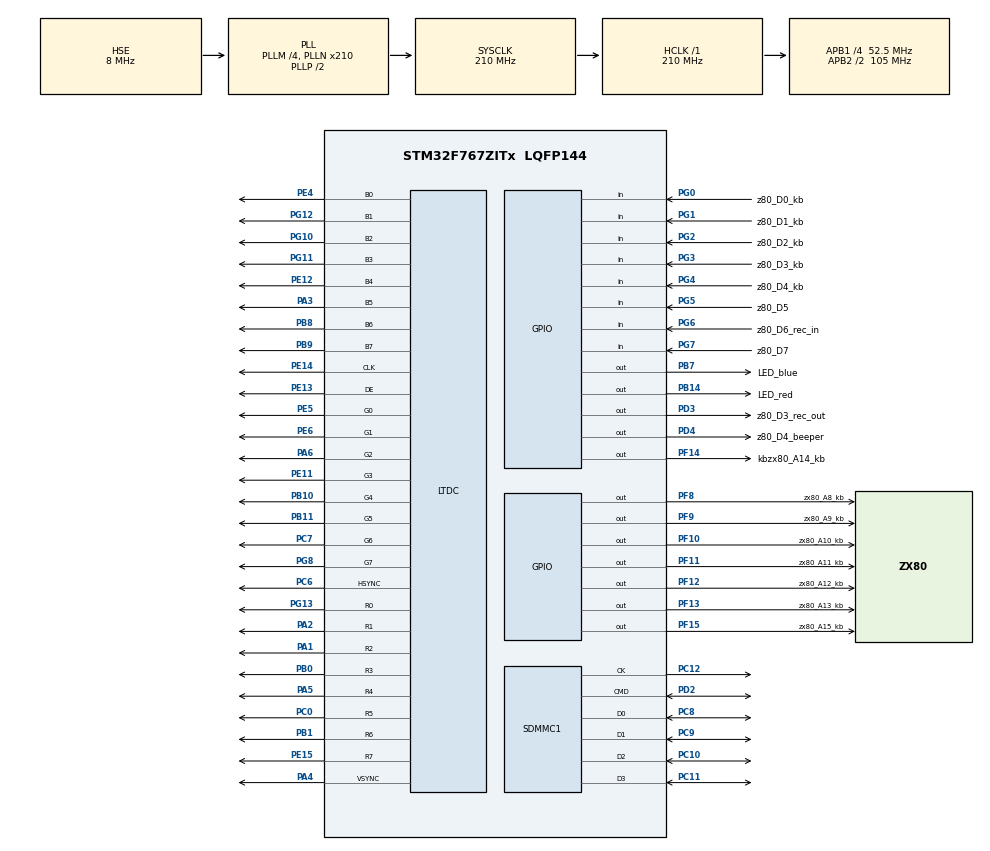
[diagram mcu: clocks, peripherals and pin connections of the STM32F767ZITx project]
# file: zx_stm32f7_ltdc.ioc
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CORTEX_M7.CPU_DCache=Enabled
CORTEX_M7.CPU_ICache=Enabled
CORTEX_M7.FlashInterface=TCM_Enabled
CORTEX_M7.PREFETCH_ENABLE=1
Dma.MEMTOMEM.0.Direction=DMA_MEMORY_TO_MEMORY
Dma.MEMTOMEM.0.FIFOMode=DMA_FIFOMODE_ENABLE
Dma.MEMTOMEM.0.FIFOThreshold=DMA_FIFO_THRESHOLD_FULL
Dma.MEMTOMEM.0.Instance=DMA2_Stream1
Dma.MEMTOMEM.0.MemBurst=DMA_MBURST_SINGLE
Dma.MEMTOMEM.0.MemDataAlignment=DMA_MDATAALIGN_HALFWORD
Dma.MEMTOMEM.0.MemInc=DMA_MINC_ENABLE
Dma.MEMTOMEM.0.Mode=DMA_NORMAL
Dma.MEMTOMEM.0.PeriphBurst=DMA_PBURST_SINGLE
Dma.MEMTOMEM.0.PeriphDataAlignment=DMA_PDATAALIGN_HALFWORD
Dma.MEMTOMEM.0.PeriphInc=DMA_PINC_ENABLE
Dma.MEMTOMEM.0.Priority=DMA_PRIORITY_HIGH
Dma.Request0=MEMTOMEM
FATFS.USE_DMA_CODE_SD=0
FATFS._MAX_SS=4096
LTDC.ActiveH=272
LTDC.ActiveW=384
LTDC.Alpha0_L0=0
LTDC.Alpha_L0=255
LTDC.BlendingFactor1_L0=LTDC_BLENDING_FACTOR1_PAxCA
LTDC.BlendingFactor2_L0=LTDC_BLENDING_FACTOR2_PAxCA
LTDC.DEPolarity=LTDC_DEPOLARITY_AL
LTDC.HBP=42
LTDC.HFP=8
LTDC.HSPolarity=LTDC_HSPOLARITY_AL
LTDC.HSync=14
LTDC.ImageHeight_L0=192
LTDC.ImageWidth_L0=256
LTDC.Layers=0
LTDC.PixelFormat_L0=LTDC_PIXEL_FORMAT_RGB565
LTDC.VBP=12
LTDC.VFP=4
LTDC.VSPolarity=LTDC_VSPOLARITY_AL
LTDC.VSync=32
LTDC.WindowX0_L0=64
LTDC.WindowX1_L0=320
LTDC.WindowY0_L0=40
LTDC.WindowY1_L0=232
Mcu.Family=STM32F7
Mcu.Name=STM32F767ZITx
Mcu.Package=LQFP144
NVIC.PriorityGroup=NVIC_PRIORITYGROUP_4
NVIC.TIM8_TRG_COM_TIM14_IRQn=true\:0\:0\:false\:false\:true\:true
PA1.GPIO_Speed=GPIO_SPEED_FREQ_VERY_HIGH
PA1.Mode=RGB888
PA1.Signal=LTDC_R2
PA2.GPIO_Speed=GPIO_SPEED_FREQ_VERY_HIGH
PA2.Mode=RGB888
PA2.Signal=LTDC_R1
PA3.GPIO_Speed=GPIO_SPEED_FREQ_VERY_HIGH
PA3.Mode=RGB888
PA3.Signal=LTDC_B5
PA4.GPIO_Speed=GPIO_SPEED_FREQ_VERY_HIGH
PA4.Mode=RGB888
PA4.Signal=LTDC_VSYNC
PA5.GPIO_Speed=GPIO_SPEED_FREQ_VERY_HIGH
PA5.Mode=RGB888
PA5.Signal=LTDC_R4
PA6.GPIO_Speed=GPIO_SPEED_FREQ_VERY_HIGH
PA6.Mode=RGB888
PA6.Signal=LTDC_G2
PB0.GPIO_Speed=GPIO_SPEED_FREQ_VERY_HIGH
PB0.Mode=RGB888
PB0.Signal=LTDC_R3
PB1.GPIO_Speed=GPIO_SPEED_FREQ_VERY_HIGH
PB1.Mode=RGB888
PB1.Signal=LTDC_R6
PB10.GPIO_Speed=GPIO_SPEED_FREQ_VERY_HIGH
PB10.Mode=RGB888
PB10.Signal=LTDC_G4
PB11.GPIO_Speed=GPIO_SPEED_FREQ_VERY_HIGH
PB11.Mode=RGB888
PB11.Signal=LTDC_G5
PB14.GPIO_Label=LED_red
PB14.GPIO_Speed=GPIO_SPEED_FREQ_HIGH
PB14.Signal=GPIO_Output
PB7.GPIO_Label=LED_blue
PB7.GPIO_Speed=GPIO_SPEED_FREQ_HIGH
PB7.Signal=GPIO_Output
PB8.GPIO_Speed=GPIO_SPEED_FREQ_VERY_HIGH
PB8.Mode=RGB888
PB8.Signal=LTDC_B6
PB9.GPIO_Speed=GPIO_SPEED_FREQ_VERY_HIGH
PB9.Mode=RGB888
PB9.Signal=LTDC_B7
PC0.GPIO_Speed=GPIO_SPEED_FREQ_VERY_HIGH
PC0.Mode=RGB888
PC0.Signal=LTDC_R5
PC10.GPIO_PuPd=GPIO_PULLUP
PC10.Mode=SD_4_bits_Wide_bus
PC10.Signal=SDMMC1_D2
PC11.GPIO_PuPd=GPIO_PULLUP
PC11.Mode=SD_4_bits_Wide_bus
PC11.Signal=SDMMC1_D3
PC12.GPIO_PuPd=GPIO_PULLUP
PC12.Mode=SD_4_bits_Wide_bus
PC12.Signal=SDMMC1_CK
PC6.GPIO_Speed=GPIO_SPEED_FREQ_VERY_HIGH
PC6.Mode=RGB888
PC6.Signal=LTDC_HSYNC
PC7.GPIO_Speed=GPIO_SPEED_FREQ_VERY_HIGH
PC7.Mode=RGB888
PC7.Signal=LTDC_G6
PC8.GPIO_PuPd=GPIO_PULLUP
PC8.Mode=SD_4_bits_Wide_bus
PC8.Signal=SDMMC1_D0
PC9.GPIO_PuPd=GPIO_PULLUP
PC9.Mode=SD_4_bits_Wide_bus
PC9.Signal=SDMMC1_D1
PD2.GPIO_PuPd=GPIO_PULLUP
PD2.Mode=SD_4_bits_Wide_bus
PD2.Signal=SDMMC1_CMD
PD3.GPIO_Label=z80_D3_rec_out
PD3.GPIO_Speed=GPIO_SPEED_FREQ_HIGH
PD3.Signal=GPIO_Output
PD4.GPIO_Label=z80_D4_beeper
PD4.GPIO_Speed=GPIO_SPEED_FREQ_HIGH
PD4.Signal=GPIO_Output
PE11.GPIO_Speed=GPIO_SPEED_FREQ_VERY_HIGH
PE11.Mode=RGB888
PE11.Signal=LTDC_G3
PE12.GPIO_Speed=GPIO_SPEED_FREQ_VERY_HIGH
PE12.Mode=RGB888
PE12.Signal=LTDC_B4
PE13.GPIO_Speed=GPIO_SPEED_FREQ_VERY_HIGH
PE13.Mode=RGB888
PE13.Signal=LTDC_DE
PE14.GPIO_Speed=GPIO_SPEED_FREQ_VERY_HIGH
PE14.Mode=RGB888
PE14.Signal=LTDC_CLK
PE15.GPIO_Speed=GPIO_SPEED_FREQ_VERY_HIGH
PE15.Mode=RGB888
PE15.Signal=LTDC_R7
PE4.GPIO_Speed=GPIO_SPEED_FREQ_VERY_HIGH
PE4.Mode=RGB888
PE4.Signal=LTDC_B0
PE5.GPIO_Speed=GPIO_SPEED_FREQ_VERY_HIGH
PE5.Mode=RGB888
PE5.Signal=LTDC_G0
PE6.GPIO_Speed=GPIO_SPEED_FREQ_VERY_HIGH
PE6.Mode=RGB888
PE6.Signal=LTDC_G1
PF10.GPIO_Label=zx80_A10_kb
PF10.GPIO_ModeDefaultOutputPP=GPIO_MODE_OUTPUT_OD
PF10.GPIO_PuPd=GPIO_PULLUP
PF10.GPIO_Speed=GPIO_SPEED_FREQ_VERY_HIGH
PF10.Signal=GPIO_Output
PF11.GPIO_Label=zx80_A11_kb
PF11.GPIO_ModeDefaultOutputPP=GPIO_MODE_OUTPUT_OD
PF11.GPIO_PuPd=GPIO_PULLUP
PF11.GPIO_Speed=GPIO_SPEED_FREQ_VERY_HIGH
PF11.Signal=GPIO_Output
PF12.GPIO_Label=zx80_A12_kb
PF12.GPIO_ModeDefaultOutputPP=GPIO_MODE_OUTPUT_OD
PF12.GPIO_PuPd=GPIO_PULLUP
PF12.GPIO_Speed=GPIO_SPEED_FREQ_VERY_HIGH
PF12.Signal=GPIO_Output
PF13.GPIO_Label=zx80_A13_kb
PF13.GPIO_ModeDefaultOutputPP=GPIO_MODE_OUTPUT_OD
PF13.GPIO_PuPd=GPIO_PULLUP
PF13.GPIO_Speed=GPIO_SPEED_FREQ_VERY_HIGH
PF13.Signal=GPIO_Output
PF14.GPIO_Label=kbzx80_A14_kb
PF14.GPIO_ModeDefaultOutputPP=GPIO_MODE_OUTPUT_OD
PF14.GPIO_PuPd=GPIO_PULLUP
PF14.GPIO_Speed=GPIO_SPEED_FREQ_VERY_HIGH
PF14.Signal=GPIO_Output
PF15.GPIO_Label=zx80_A15_kb
PF15.GPIO_ModeDefaultOutputPP=GPIO_MODE_OUTPUT_OD
PF15.GPIO_PuPd=GPIO_PULLUP
PF15.GPIO_Speed=GPIO_SPEED_FREQ_VERY_HIGH
PF15.Signal=GPIO_Output
PF8.GPIO_Label=zx80_A8_kb
PF8.GPIO_ModeDefaultOutputPP=GPIO_MODE_OUTPUT_OD
PF8.GPIO_PuPd=GPIO_PULLUP
PF8.GPIO_Speed=GPIO_SPEED_FREQ_VERY_HIGH
PF8.Signal=GPIO_Output
PF9.GPIO_Label=zx80_A9_kb
PF9.GPIO_ModeDefaultOutputPP=GPIO_MODE_OUTPUT_OD
PF9.GPIO_PuPd=GPIO_PULLUP
PF9.GPIO_Speed=GPIO_SPEED_FREQ_VERY_HIGH
PF9.Signal=GPIO_Output
PG0.GPIO_Label=z80_D0_kb
PG0.GPIO_Mode=GPIO_MODE_INPUT
PG0.GPIO_PuPd=GPIO_PULLUP
PG0.Signal=GPIO_Input
PG1.GPIO_Label=z80_D1_kb
PG1.GPIO_Mode=GPIO_MODE_INPUT
PG1.GPIO_PuPd=GPIO_PULLUP
PG1.Signal=GPIO_Input
PG10.GPIO_Speed=GPIO_SPEED_FREQ_VERY_HIGH
PG10.Mode=RGB888
PG10.Signal=LTDC_B2
PG11.GPIO_Speed=GPIO_SPEED_FREQ_VERY_HIGH
PG11.Mode=RGB888
PG11.Signal=LTDC_B3
PG12.GPIO_Speed=GPIO_SPEED_FREQ_VERY_HIGH
PG12.Mode=RGB888
PG12.Signal=LTDC_B1
PG13.GPIO_Speed=GPIO_SPEED_FREQ_VERY_HIGH
PG13.Mode=RGB888
PG13.Signal=LTDC_R0
PG2.GPIO_Label=z80_D2_kb
PG2.GPIO_Mode=GPIO_MODE_INPUT
PG2.GPIO_PuPd=GPIO_PULLUP
PG2.Signal=GPIO_Input
PG3.GPIO_Label=z80_D3_kb
PG3.GPIO_Mode=GPIO_MODE_INPUT
PG3.GPIO_PuPd=GPIO_PULLUP
PG3.Signal=GPIO_Input
PG4.GPIO_Label=z80_D4_kb
PG4.GPIO_Mode=GPIO_MODE_INPUT
PG4.GPIO_PuPd=GPIO_PULLUP
PG4.Signal=GPIO_Input
PG5.GPIO_Label=z80_D5
PG5.GPIO_Mode=GPIO_MODE_INPUT
PG5.GPIO_PuPd=GPIO_PULLUP
PG5.Signal=GPIO_Input
PG6.GPIO_Label=z80_D6_rec_in
PG6.GPIO_Mode=GPIO_MODE_INPUT
PG6.GPIO_PuPd=GPIO_PULLUP
PG6.Signal=GPIO_Input
PG7.GPIO_Label=z80_D7
PG7.GPIO_Mode=GPIO_MODE_INPUT
PG7.GPIO_PuPd=GPIO_PULLUP
PG7.Signal=GPIO_Input
PG8.GPIO_Speed=GPIO_SPEED_FREQ_VERY_HIGH
PG8.Mode=RGB888
PG8.Signal=LTDC_G7
PH0/OSC_IN.Mode=HSE-External-Oscillator
PH0/OSC_IN.Signal=RCC_OSC_IN
PH1/OSC_OUT.Mode=HSE-External-Oscillator
PH1/OSC_OUT.Signal=RCC_OSC_OUT
ProjectManager.HeapSize=0x200
ProjectManager.StackSize=0x400
ProjectManager.TargetToolchain=SW4STM32
RCC.AHBFreq_Value=210000000
RCC.APB1CLKDivider=RCC_HCLK_DIV4
RCC.APB1Freq_Value=52500000
RCC.APB1TimFreq_Value=105000000
RCC.APB2CLKDivider=RCC_HCLK_DIV2
RCC.APB2Freq_Value=105000000
RCC.APB2TimFreq_Value=210000000
RCC.CortexFreq_Value=210000000
RCC.HCLKFreq_Value=210000000
RCC.HSE_VALUE=8000000
RCC.HSI_VALUE=16000000
RCC.LSE_VALUE=32768
RCC.PLLM=4
RCC.PLLN=210
RCC.PLLQ=15
RCC.PLLSAIN=98
RCC.PLLSAIP=RCC_PLLSAIP_DIV6
RCC.PLLSAIR=7
RCC.PLLSAIRDiv=RCC_PLLSAIDIVR_4
RCC.PLLSourceVirtual=RCC_PLLSOURCE_HSE
RCC.SDMMCClockSelection=RCC_SDMMC1CLKSOURCE_CLK48
RCC.SYSCLKFreq_VALUE=210000000
RCC.SYSCLKSource=RCC_SYSCLKSOURCE_PLLCLK
RCC.USBFreq_Value=28000000
RCC.VCOOutputFreq_Value=420000000
TIM13.AutoReloadPreload=TIM_AUTORELOAD_PRELOAD_ENABLE
TIM13.Channel=TIM_CHANNEL_1
TIM13.Period=10239
TIM13.Prescaler=209
TIM14.Channel=TIM_CHANNEL_1
TIM14.Period=65535
TIM14.Prescaler=29
VP_FATFS_VS_SDIO.Mode=SDIO
VP_RNG_VS_RNG.Mode=RNG_Activate
VP_TIM13_VS_ClockSourceINT.Mode=Enable_Timer
VP_TIM13_VS_no_output1.Mode=Output Compare1 No Output
VP_TIM14_VS_ClockSourceINT.Mode=Enable_Timer
VP_TIM14_VS_no_output1.Mode=Output Compare1 No Output
board=zx_stm32f7_ltdc

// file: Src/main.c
/**
  ******************************************************************************
  * @file           : main.c
  * @brief          : Main program body
  ******************************************************************************
  * This notice applies to any and all portions of this file
  * that are not between comment pairs USER CODE BEGIN and
  * USER CODE END. Other portions of this file, whether
  * inserted by the user or by software development tools
  * are owned by their respective copyright owners.
  *
  * Copyright (c) 2018 STMicroelectronics International N.V.
  * All rights reserved.
  *
  * Redistribution and use in source and binary forms, with or without
  * modification, are permitted, provided that the following conditions are met:
  *
  * 1. Redistribution of source code must retain the above copyright notice,
  *    this list of conditions and the following disclaimer.
  * 2. Redistributions in binary form must reproduce the above copyright notice,
  *    this list of conditions and the following disclaimer in the documentation
  *    and/or other materials provided with the distribution.
  * 3. Neither the name of STMicroelectronics nor the names of other
  *    contributors to this software may be used to endorse or promote products
  *    derived from this software without specific written permission.
  * 4. This software, including modifications and/or derivative works of this
  *    software, must execute solely and exclusively on microcontroller or
  *    microprocessor devices manufactured by or for STMicroelectronics.
  * 5. Redistribution and use of this software other than as permitted under
  *    this license is void and will automatically terminate your rights under
  *    this license.
  *
  * THIS SOFTWARE IS PROVIDED BY STMICROELECTRONICS AND CONTRIBUTORS "AS IS"
  * AND ANY EXPRESS, IMPLIED OR STATUTORY WARRANTIES, INCLUDING, BUT NOT
  * LIMITED TO, THE IMPLIED WARRANTIES OF MERCHANTABILITY, FITNESS FOR A
  * PARTICULAR PURPOSE AND NON-INFRINGEMENT OF THIRD PARTY INTELLECTUAL PROPERTY
  * RIGHTS ARE DISCLAIMED TO THE FULLEST EXTENT PERMITTED BY LAW. IN NO EVENT
  * SHALL STMICROELECTRONICS OR CONTRIBUTORS BE LIABLE FOR ANY DIRECT, INDIRECT,
  * INCIDENTAL, SPECIAL, EXEMPLARY, OR CONSEQUENTIAL DAMAGES (INCLUDING, BUT NOT
  * LIMITED TO, PROCUREMENT OF SUBSTITUTE GOODS OR SERVICES; LOSS OF USE, DATA,
  * OR PROFITS; OR BUSINESS INTERRUPTION) HOWEVER CAUSED AND ON ANY THEORY OF
  * LIABILITY, WHETHER IN CONTRACT, STRICT LIABILITY, OR TORT (INCLUDING
  * NEGLIGENCE OR OTHERWISE) ARISING IN ANY WAY OUT OF THE USE OF THIS SOFTWARE,
  * EVEN IF ADVISED OF THE POSSIBILITY OF SUCH DAMAGE.
  *
  ******************************************************************************
  */
#include "main.h"
#include "stm32f7xx_hal.h"
#include "dma.h"
#include "fatfs.h"
#include "ltdc.h"
#include "rng.h"
#include "sdmmc.h"
#include "tim.h"
#include "gpio.h"

/* USER CODE BEGIN Includes */
#include "zx80.h"
/* USER CODE END Includes */

/* USER CODE BEGIN PV */
/* Private variables ---------------------------------------------------------*/

/* USER CODE END PV */

void SystemClock_Config(void);

/* USER CODE BEGIN PFP */
/* Private function prototypes -----------------------------------------------*/

/* USER CODE END PFP */

int main(void)
{

  /* Enable I-Cache-------------------------------------------------------------*/
  SCB_EnableICache();

  /* Enable D-Cache-------------------------------------------------------------*/
  SCB_EnableDCache();

  /* MCU Configuration----------------------------------------------------------*/

  /* Reset of all peripherals, Initializes the Flash interface and the Systick. */
  HAL_Init();

  /* Configure the system clock */
  SystemClock_Config();

  /* Initialize all configured peripherals */
  MX_GPIO_Init();
  MX_DMA_Init();
  MX_LTDC_Init();
  MX_RNG_Init();
  MX_TIM14_Init();
  MX_TIM13_Init();
  MX_SDMMC1_SD_Init();
  MX_FATFS_Init();
  /* USER CODE BEGIN 2 */

  //zx80_Init();
  zx80_load();

  /* USER CODE END 2 */

  /* Infinite loop */
  while (1)
  {

  }

}

void SystemClock_Config(void)
{

  RCC_OscInitTypeDef RCC_OscInitStruct;
  RCC_ClkInitTypeDef RCC_ClkInitStruct;
  RCC_PeriphCLKInitTypeDef PeriphClkInitStruct;

    /**Configure the main internal regulator output voltage
    */
  __HAL_RCC_PWR_CLK_ENABLE();

  __HAL_PWR_VOLTAGESCALING_CONFIG(PWR_REGULATOR_VOLTAGE_SCALE1);

    /**Initializes the CPU, AHB and APB busses clocks
    */
  RCC_OscInitStruct.OscillatorType = RCC_OSCILLATORTYPE_HSE;
  RCC_OscInitStruct.HSEState = RCC_HSE_ON;
  RCC_OscInitStruct.PLL.PLLState = RCC_PLL_ON;
  RCC_OscInitStruct.PLL.PLLSource = RCC_PLLSOURCE_HSE;
  RCC_OscInitStruct.PLL.PLLM = 4;
  RCC_OscInitStruct.PLL.PLLN = 210;
  RCC_OscInitStruct.PLL.PLLP = RCC_PLLP_DIV2;
  RCC_OscInitStruct.PLL.PLLQ = 15;
  if (HAL_RCC_OscConfig(&RCC_OscInitStruct) != HAL_OK)
  {
    _Error_Handler(__FILE__, __LINE__);
  }

    /**Activate the Over-Drive mode
    */
  if (HAL_PWREx_EnableOverDrive() != HAL_OK)
  {
    _Error_Handler(__FILE__, __LINE__);
  }

    /**Initializes the CPU, AHB and APB busses clocks
    */
  RCC_ClkInitStruct.ClockType = RCC_CLOCKTYPE_HCLK|RCC_CLOCKTYPE_SYSCLK
                              |RCC_CLOCKTYPE_PCLK1|RCC_CLOCKTYPE_PCLK2;
  RCC_ClkInitStruct.SYSCLKSource = RCC_SYSCLKSOURCE_PLLCLK;
  RCC_ClkInitStruct.AHBCLKDivider = RCC_SYSCLK_DIV1;
  RCC_ClkInitStruct.APB1CLKDivider = RCC_HCLK_DIV4;
  RCC_ClkInitStruct.APB2CLKDivider = RCC_HCLK_DIV2;

  if (HAL_RCC_ClockConfig(&RCC_ClkInitStruct, FLASH_LATENCY_6) != HAL_OK)
  {
    _Error_Handler(__FILE__, __LINE__);
  }

  PeriphClkInitStruct.PeriphClockSelection = RCC_PERIPHCLK_LTDC|RCC_PERIPHCLK_SDMMC1
                              |RCC_PERIPHCLK_CLK48;
  PeriphClkInitStruct.PLLSAI.PLLSAIN = 98;
  PeriphClkInitStruct.PLLSAI.PLLSAIR = 7;
  PeriphClkInitStruct.PLLSAI.PLLSAIQ = 2;
  PeriphClkInitStruct.PLLSAI.PLLSAIP = RCC_PLLSAIP_DIV6;
  PeriphClkInitStruct.PLLSAIDivQ = 1;
  PeriphClkInitStruct.PLLSAIDivR = RCC_PLLSAIDIVR_4;
  PeriphClkInitStruct.Clk48ClockSelection = RCC_CLK48SOURCE_PLL;
  PeriphClkInitStruct.Sdmmc1ClockSelection = RCC_SDMMC1CLKSOURCE_CLK48;
  if (HAL_RCCEx_PeriphCLKConfig(&PeriphClkInitStruct) != HAL_OK)
  {
    _Error_Handler(__FILE__, __LINE__);
  }

    /**Configure the Systick interrupt time
    */
  HAL_SYSTICK_Config(HAL_RCC_GetHCLKFreq()/1000);

    /**Configure the Systick
    */
  HAL_SYSTICK_CLKSourceConfig(SYSTICK_CLKSOURCE_HCLK);

  /* SysTick_IRQn interrupt configuration */
  HAL_NVIC_SetPriority(SysTick_IRQn, 0, 0);
}

void _Error_Handler(char *file, int line)
{
  while(1)
  {
  }
}

/************************ (C) COPYRIGHT STMicroelectronics *****END OF FILE****/
